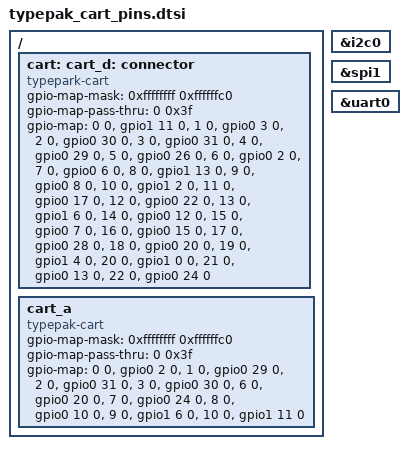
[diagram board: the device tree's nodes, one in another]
/ {
    cart: connector {
        compatible = "typepark-cart";
        #gpio-cells = <2>;
        gpio-map-mask = <0xffffffff 0xffffffc0>;
        gpio-map-pass-thru = <0 0x3f>;
        gpio-map
            = <0 0 &gpio1 11 0>
            , <1 0 &gpio0 3 0>
            , <2 0 &gpio0 30 0>
            , <3 0 &gpio0 31 0>
            , <4 0 &gpio0 29 0>
            , <5 0 &gpio0 26 0>
            , <6 0 &gpio0 2 0>
            , <7 0 &gpio0 6 0>
            , <8 0 &gpio1 13 0>
            , <9 0 &gpio0 8 0>
            , <10 0 &gpio1 2 0>
            , <11 0 &gpio0 17 0>
            , <12 0 &gpio0 22 0>
            , <13 0 &gpio1 6 0>
            , <14 0 &gpio0 12 0>
            , <15 0 &gpio0 7 0>
            , <16 0 &gpio0 15 0>
            , <17 0 &gpio0 28 0>
            , <18 0 &gpio0 20 0>
            , <19 0 &gpio1 4 0>
            , <20 0 &gpio1 0 0>
            , <21 0 &gpio0 13 0>
            , <22 0 &gpio0 24 0>
            ;
    };

    cart_a: cart_a {
        compatible = "typepak-cart";
        #gpio-cells = <2>;
        gpio-map-mask = <0xffffffff 0xffffffc0>;
        gpio-map-pass-thru = <0 0x3f>;
        gpio-map
            = <0 0 &gpio0 2 0>  /* D18/A0 */
            , <1 0 &gpio0 29 0> /* D19/A1 */
            , <2 0 &gpio0 31 0> /* D20/A2 */
            , <3 0 &gpio0 30 0> /* D21/A3 */
            , <6 0 &gpio0 20 0> /* D4/A6 */
            , <7 0 &gpio0 24 0> /* D6/A7 */
            , <8 0 &gpio0 10 0> /* D8/A8 */
            , <9 0 &gpio1 6 0>  /* D9/A9 */
            , <10 0 &gpio1 11 0>    /* D10/A10 */
            ;
    };
};


cart_d: &cart {};
cart_i2c: &i2c0 {};
cart_spi: &spi1 {};
cart_serial: &uart0 {};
